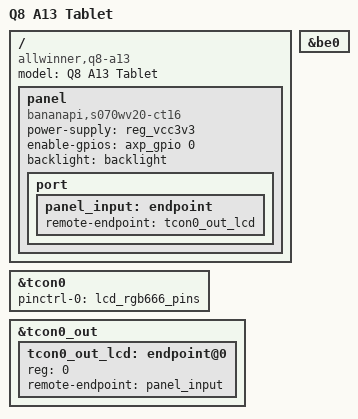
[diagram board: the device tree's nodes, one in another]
/dts-v1/;
#include "sun5i-a13.dtsi"
#include "sun5i-reference-design-tablet.dtsi"
/ {
	model = "Q8 A13 Tablet";
	compatible = "allwinner,q8-a13", "allwinner,sun5i-a13";
	panel: panel {
		compatible = "bananapi,s070wv20-ct16";
		power-supply = <&reg_vcc3v3>;
		enable-gpios = <&axp_gpio 0 GPIO_ACTIVE_HIGH>;  
		backlight = <&backlight>;
		port {
			panel_input: endpoint {
				remote-endpoint = <&tcon0_out_lcd>;
			};
		};
	};
};
&be0 {
	status = "okay";
};
&tcon0 {
	pinctrl-names = "default";
	pinctrl-0 = <&lcd_rgb666_pins>;
	status = "okay";
};
&tcon0_out {
	tcon0_out_lcd: endpoint@0 {
		reg = <0>;
		remote-endpoint = <&panel_input>;
	};
};
